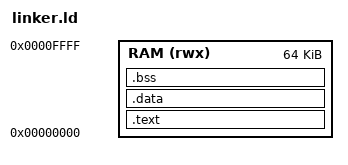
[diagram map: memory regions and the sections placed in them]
ENTRY(_start)

MEMORY
{
    RAM (rwx) : ORIGIN = 0x00000000, LENGTH = 64K
}

SECTIONS
{
    .text :
    {
        KEEP(*(.text.startup))
        *(.text .text.*)
        *(.rodata .rodata.*)
        . = ALIGN(4);
    } > RAM

    .data :
    {
        *(.data .data.*)
        *(.sdata .sdata.*)
        . = ALIGN(4);
    } > RAM

    .bss (NOLOAD) :
    {
        __bss_start = .;
        *(.sbss .sbss.*)
        *(.bss .bss.*)
        *(COMMON)
        . = ALIGN(16);
        __bss_end = .;
    } > RAM

    . = ALIGN(16);
    __heap_start = .;
    __stack_top = ORIGIN(RAM) + LENGTH(RAM);

    /DISCARD/ :
    {
        *(.comment)
        *(.note*)
        *(.eh_frame*)
        *(.riscv.attributes)
    }
}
